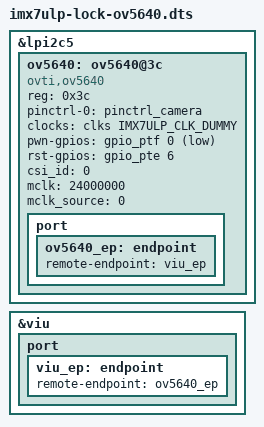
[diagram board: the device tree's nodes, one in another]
/*
 * Copyright 2016 Freescale Semiconductor, Inc.
 * Copyright 2017 NXP.
 *
 * This program is free software; you can redistribute it and/or modify
 * it under the terms of the GNU General Public License version 2 as
 * published by the Free Software Foundation.
 */

/dts-v1/;

#include "imx7ulp-lock.dts"
#include <dt-bindings/input/input.h>

&lpi2c5 {
	ov5640: ov5640@3c {
		compatible = "ovti,ov5640";
		reg = <0x3c>;
		pinctrl-names = "default";
		pinctrl-0 = <&pinctrl_camera>;
		clocks = <&clks IMX7ULP_CLK_DUMMY>;
		clock-names = "csi_mclk";
		pwn-gpios = <&gpio_ptf 0 GPIO_ACTIVE_LOW>;
		rst-gpios = <&gpio_pte 6 GPIO_ACTIVE_HIGH>;
		csi_id = <0>;
		mclk = <24000000>;
		mclk_source = <0>;
		status = "okay";

		port {
			ov5640_ep: endpoint {
				remote-endpoint = <&viu_ep>;
			};
		};
	};
};

&viu {
	status = "okay";

	port {
		viu_ep: endpoint {
			remote-endpoint = <&ov5640_ep>;
		};
	};
};

